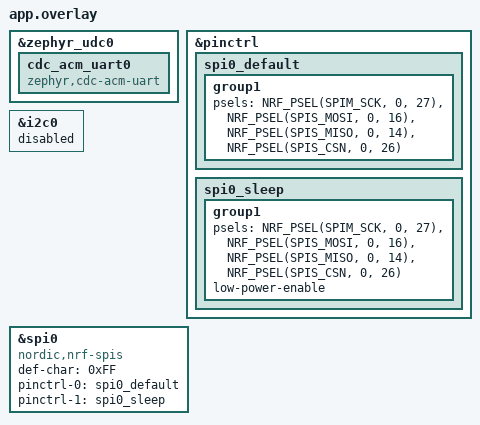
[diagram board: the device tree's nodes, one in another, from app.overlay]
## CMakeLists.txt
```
# SPDX-License-Identifier: Apache-2.0

cmake_minimum_required(VERSION 3.20.0)

find_package(Zephyr REQUIRED HINTS $ENV{ZEPHYR_BASE})
project(ioxp_emu)

target_sources(app PRIVATE
    ${PROJECT_SOURCE_DIR}/src/ipi.c
    ${PROJECT_SOURCE_DIR}/src/main.cpp
    ${PROJECT_SOURCE_DIR}/src/erpc/port/erpc_port_zephyr.cpp
    ${PROJECT_SOURCE_DIR}/src/erpc/port/erpc_threading_zephyr.cpp
    ${PROJECT_SOURCE_DIR}/src/erpc/transport/erpc_zephyr_usb_cdc_transport.cpp
    ${CMAKE_CURRENT_BINARY_DIR}/erpcgen/ioxp_pc2emu_server.cpp
    ${CMAKE_CURRENT_BINARY_DIR}/erpcgen/ioxp_emu2pc_client.cpp
    ${PROJECT_SOURCE_DIR}/../erpc/erpc_c/infra/erpc_server.cpp
    ${PROJECT_SOURCE_DIR}/../erpc/erpc_c/infra/erpc_framed_transport.cpp
    ${PROJECT_SOURCE_DIR}/../erpc/erpc_c/infra/erpc_crc16.cpp
    ${PROJECT_SOURCE_DIR}/../erpc/erpc_c/infra/erpc_message_buffer.cpp
    ${PROJECT_SOURCE_DIR}/../erpc/erpc_c/infra/erpc_simple_server.cpp
    ${PROJECT_SOURCE_DIR}/../erpc/erpc_c/infra/erpc_basic_codec.cpp
    ${PROJECT_SOURCE_DIR}/../erpc/erpc_c/infra/erpc_arbitrated_client_manager.cpp
    ${PROJECT_SOURCE_DIR}/../erpc/erpc_c/infra/erpc_transport_arbitrator.cpp
    ${PROJECT_SOURCE_DIR}/../erpc/erpc_c/infra/erpc_client_manager.cpp
    ${PROJECT_SOURCE_DIR}/../erpc/erpc_c/setup/erpc_setup_mbf_dynamic.cpp
    ${PROJECT_SOURCE_DIR}/../erpc/erpc_c/setup/erpc_arbitrated_client_setup.cpp
    ${PROJECT_SOURCE_DIR}/../erpc/erpc_c/setup/erpc_server_setup.cpp
)

target_include_directories(app PRIVATE
    ${PROJECT_SOURCE_DIR}/src/config
    ${PROJECT_SOURCE_DIR}/src/erpc/transport
    ${PROJECT_SOURCE_DIR}/src/erpc/port
    ${CMAKE_CURRENT_BINARY_DIR}/erpcgen
    ${PROJECT_SOURCE_DIR}/../erpc/erpc_c/infra
    ${PROJECT_SOURCE_DIR}/../erpc/erpc_c/transports
    ${PROJECT_SOURCE_DIR}/../erpc/erpc_c/setup

)

add_custom_command(
    OUTPUT ${CMAKE_CURRENT_BINARY_DIR}/erpcgen/ioxp_pc2emu_server.cpp
           ${CMAKE_CURRENT_BINARY_DIR}/erpcgen/ioxp_emu2pc_client.cpp
    COMMAND erpcgen -o ${CMAKE_CURRENT_BINARY_DIR}/erpcgen ${PROJECT_SOURCE_DIR}/../../shared/interface.erpc
)
```

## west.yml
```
manifest:
  remotes:
    - name: zephyrproject-rtos
      url-base: https://github.com/zephyrproject-rtos
    - name: EmbeddedRPC
      url-base: https://github.com/EmbeddedRPC
  projects:
    - name: zephyr
      remote: zephyrproject-rtos
      revision: zephyr-v3.4.0
      import:
        name-allowlist:
          - cmsis
          - hal_nordic
          - mbedtls
          - mcuboot
          - mcumgr
          - nrf_hw_models
          - segger
          - tinycbor
          - tinycrypt
          - zcbor

    - name: erpc
      remote: EmbeddedRPC
      revision: 1.10.0

  self:
    path: app
```

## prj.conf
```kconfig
CONFIG_USB_COMPOSITE_DEVICE=y
CONFIG_USB_DEVICE_STACK=y
CONFIG_USB_DEVICE_PRODUCT="IOExp"
CONFIG_USB_DEVICE_PID=0x0003
CONFIG_USB_DEVICE_INITIALIZE_AT_BOOT=n
CONFIG_ENTROPY_GENERATOR=y
CONFIG_ENTROPY_DEVICE_RANDOM_GENERATOR=y

CONFIG_LOG=y
CONFIG_USB_DRIVER_LOG_LEVEL_INF=y
CONFIG_USB_DEVICE_LOG_LEVEL_INF=y

CONFIG_SERIAL=y
CONFIG_UART_LINE_CTRL=y

CONFIG_GPIO=y

CONFIG_CPP=y
CONFIG_NEWLIB_LIBC=y
CONFIG_REQUIRES_FULL_LIBCPP=y

CONFIG_HEAP_MEM_POOL_SIZE=8192

CONFIG_SHELL=y
CONFIG_THREAD_RUNTIME_STATS=y
CONFIG_STATS=y
CONFIG_STATS_SHELL=y

CONFIG_PIPES=y

CONFIG_DEBUG_OPTIMIZATIONS=y

CONFIG_MAIN_STACK_SIZE=8192

CONFIG_DEBUG=y

CONFIG_SPI=y
CONFIG_SPI_SLAVE=y
CONFIG_SPI_ASYNC=y
```

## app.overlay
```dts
/*
 * Copyright (c) 2021 Nordic Semiconductor ASA
 *
 * SPDX-License-Identifier: Apache-2.0
 */

&zephyr_udc0 {
	cdc_acm_uart0 {
		compatible = "zephyr,cdc-acm-uart";
	};

};

&pinctrl {

	spi0_default: spi0_default {
		group1 {
			psels = <NRF_PSEL(SPIM_SCK, 0, 27)>, 
			<NRF_PSEL(SPIS_MOSI, 0, 16)>,
			<NRF_PSEL(SPIS_MISO, 0, 14)>,
			<NRF_PSEL(SPIS_CSN, 0, 26)>;

		};
	};

	spi0_sleep: spi0_sleep {
		group1 {
			psels = <NRF_PSEL(SPIM_SCK, 0, 27)>, 
			<NRF_PSEL(SPIS_MOSI, 0, 16)>,
			<NRF_PSEL(SPIS_MISO, 0, 14)>,
			<NRF_PSEL(SPIS_CSN, 0, 26)>;
			low-power-enable;
		};
	};
};

// I2C0 is enabled in the board DTS, but SPI0 cannot be used
// at the same time. Thus we override the status to 'disabled' here
&i2c0 {
	status = "disabled";
};

&spi0 {
	compatible = "nordic,nrf-spis";
	status = "okay";

	def-char = <0xFF>;

	pinctrl-0 = <&spi0_default>;
	pinctrl-1 = <&spi0_sleep>;
	pinctrl-names = "default", "sleep";	
};
```

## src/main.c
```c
/*
 * Copyright (c) 2019 Nordic Semiconductor ASA
 *
 * SPDX-License-Identifier: Apache-2.0
 */
#include <zephyr/kernel.h>
#include <zephyr/device.h>
#include <zephyr/drivers/gpio.h>
#include <zephyr/drivers/uart.h>
#include <string.h>
#include <zephyr/random/rand32.h>

#include <zephyr/usb/usb_device.h>
#include <zephyr/usb/class/usb_hid.h>
#include <zephyr/usb/class/usb_cdc.h>

#define LOG_LEVEL LOG_LEVEL_DBG
LOG_MODULE_REGISTER(main);


#define MOUSE_BTN_REPORT_POS	0
#define MOUSE_X_REPORT_POS	1
#define MOUSE_Y_REPORT_POS	2

#define MOUSE_BTN_LEFT		BIT(0)
#define MOUSE_BTN_RIGHT		BIT(1)
#define MOUSE_BTN_MIDDLE	BIT(2)


#define WELCOME_MSG "Welcome ..."

/* CDC ACM */

static volatile bool data_transmitted;
static volatile bool data_arrived;

static void write_data(const struct device *dev, const char *buf, int len)
{
	uart_irq_tx_enable(dev);

	while (len) {
		int written;

		data_transmitted = false;
		written = uart_fifo_fill(dev, (const uint8_t *)buf, len);
		while (data_transmitted == false) {
			k_yield();
		}

		len -= written;
		buf += written;
	}

	uart_irq_tx_disable(dev);
}

static void cdc_0_int_handler(const struct device *dev, void *user_data)
{
	ARG_UNUSED(user_data);

	uart_irq_update(dev);

	if (uart_irq_tx_ready(dev)) {
		data_transmitted = true;
	}

	if (!uart_irq_rx_ready(dev)) {
		return;
	}
	uint32_t bytes_read;
	uint8_t rx_buffer;

	while ((bytes_read = uart_fifo_read(dev, &rx_buffer, 1))) {
		LOG_INF("char received on CDC0: 0x%02x (%c)", rx_buffer, (char) rx_buffer);
	}

}

static void cdc_1_int_handler(const struct device *dev, void *user_data)
{
	ARG_UNUSED(user_data);

	uart_irq_update(dev);

	if (uart_irq_tx_ready(dev)) {
		data_transmitted = true;
	}

	if (!uart_irq_rx_ready(dev)) {
		return;
	}
	uint32_t bytes_read;
	uint8_t rx_buffer;

	while ((bytes_read = uart_fifo_read(dev, &rx_buffer,1))) {
		LOG_INF("char received on CDC1: 0x%02x (%c)", rx_buffer, (char) rx_buffer);
	}
}

/* Devices */

static void status_cb(enum usb_dc_status_code status, const uint8_t *param)
{
	LOG_INF("Status %d", status);
}

#define DEVICE_AND_COMMA(node_id) DEVICE_DT_GET(node_id),

int main(void)
{
	const struct device *cdc_dev[] = {
		DT_FOREACH_STATUS_OKAY(zephyr_cdc_acm_uart, DEVICE_AND_COMMA)
	};
	BUILD_ASSERT(ARRAY_SIZE(cdc_dev) >= 2, "Not enough CDC ACM instances");
	uint32_t dtr = 0U;
	int ret;

	for (int idx = 0; idx < ARRAY_SIZE(cdc_dev); idx++) {
		if (!device_is_ready(cdc_dev[idx])) {
			LOG_ERR("CDC ACM device %s is not ready",
				cdc_dev[idx]->name);
			return 0;
		}
	}

	ret = usb_enable(status_cb);
	if (ret != 0) {
		LOG_ERR("Failed to enable USB");
		return 0;
	}

	/* Initialize CDC ACM */
	for (int idx = 0; idx < ARRAY_SIZE(cdc_dev); idx++) {
		LOG_INF("Wait for DTR on %s", cdc_dev[idx]->name);
		while (1) {
			uart_line_ctrl_get(cdc_dev[idx],
					   UART_LINE_CTRL_DTR,
					   &dtr);
			if (dtr) {
				break;
			} else {
				/* Give CPU resources to low priority threads. */
				k_sleep(K_MSEC(100));
			}
		}

		LOG_INF("DTR on device %s", cdc_dev[idx]->name);
	}


	LOG_INF("Waiting for 1s");
	/* Wait 1 sec for the host to do all settings */
	k_busy_wait(USEC_PER_SEC);

	uart_irq_callback_set(cdc_dev[0], cdc_0_int_handler);
	uart_irq_callback_set(cdc_dev[1], cdc_1_int_handler);

	write_data(cdc_dev[0], WELCOME_MSG, strlen(WELCOME_MSG));
	write_data(cdc_dev[0], cdc_dev[0]->name, strlen(cdc_dev[0]->name));
	write_data(cdc_dev[1], WELCOME_MSG, strlen(WELCOME_MSG));
	write_data(cdc_dev[1], cdc_dev[1]->name, strlen(cdc_dev[1]->name));

	uart_irq_rx_enable(cdc_dev[0]);
	uart_irq_rx_enable(cdc_dev[1]);

	while (true) {
		k_sleep(K_MSEC(100));
	}

}
```

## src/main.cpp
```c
/*
 * Copyright (c) 2019 Nordic Semiconductor ASA
 *
 * SPDX-License-Identifier: Apache-2.0
 */
#include <zephyr/kernel.h>
#include <zephyr/device.h>
#include <zephyr/drivers/gpio.h>
#include <zephyr/drivers/uart.h>
#include <string.h>
#include <zephyr/random/rand32.h>

#include <zephyr/usb/usb_device.h>
#include <zephyr/usb/class/usb_hid.h>
#include <zephyr/usb/class/usb_cdc.h>

#include <string>
#include "ioxp_pc2emu_server.h"

#include <erpc_server_setup.h>
#include <erpc_arbitrated_client_setup.h>
#include "erpc_zephyr_usb_cdc_transport.hpp"

#include "ipi.h"

using namespace std;

#define LOG_LEVEL LOG_LEVEL_DBG
LOG_MODULE_REGISTER(main);

static void status_cb(enum usb_dc_status_code status, const uint8_t *param)
{
	LOG_INF("Status %d", status);
}


/************************************************************************************************
 * Server Methods ...
 ***********************************************************************************************/

status_t sendCanMsg(const rvc_msg_t * txInput){

	int rc;
	status_t status = ERROR;

	char temp_buff[256];
	char* wp = temp_buff;
	char* ep = wp + sizeof(temp_buff);
	wp = wp + snprintf(wp, ep - wp,"CAN ID: 0x%08x - Data:", txInput->id);
	for(uint8_t i=0; i < 8; i++){
	 	wp = wp + snprintf(wp, ep - wp,"0x%02x ", txInput->data[i]);
	}
	*wp = '\0';

	LOG_DBG("Sending: %s", temp_buff);

	rc = ipi_send_can_msg(txInput);
	if (rc == 0) {
		status = SUCCESS;
	}
	return status;
}

int main(void)
{
	uint32_t dtr = 0U;
	int ret;

	const struct device *cdc_dev;
	cdc_dev = DEVICE_DT_GET_ONE(zephyr_cdc_acm_uart);

	if (!device_is_ready(cdc_dev)) {
		LOG_ERR("CDC ACM device not ready");
		return 0;
	}

	ret = usb_enable(status_cb);
	if (ret != 0) {
		LOG_ERR("Failed to enable USB");
		return 0;
	}

	/* Initialize CDC ACM */
	while (true) {
		uart_line_ctrl_get(cdc_dev, UART_LINE_CTRL_DTR, &dtr);
		if (dtr) {
			break;
		} else {
			/* Give CPU resources to low priority threads. */
			k_sleep(K_MSEC(100));
		}
	}

	LOG_INF("Waiting for 1s");
	/* Wait 1 sec for the host to do all settings */
	k_busy_wait(USEC_PER_SEC);


	erpc_transport_t arbitrated_transport;
	erpc_transport_t transport = reinterpret_cast<erpc_transport_t>(
		new erpc::ZephyrUsbCdcTransport(cdc_dev)
	);
	erpc_mbf_t message_buffer_factory = erpc_mbf_dynamic_init();

	erpc_client_t client = erpc_arbitrated_client_init(transport, message_buffer_factory, &arbitrated_transport);
	if (client == NULL) {
		LOG_ERR("Failed to initialize eRPC arbitrated client");
	}

	LOG_INF("Setting up server ...");
	auto server = erpc_server_init(arbitrated_transport, message_buffer_factory);

	LOG_INF("Adding service to server ... ");
	erpc_add_service_to_server(server, create_IoExpanderEmulator_service());

	LOG_INF("Starting IPI");
	ipi_init();

	LOG_INF("Starting server ...");
	erpc_server_run(server);

	// shouuld never get here ....

	while (true) {
		k_sleep(K_MSEC(100));
	}

}
```

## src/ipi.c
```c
#include "ipi.h"
#include <zephyr/kernel.h>
#include <zephyr/logging/log.h>
#include <zephyr/drivers/gpio.h>
#include <zephyr/drivers/spi.h>
#include <string.h>
#include <stdio.h>
#include "ioxp_emu2pc.h"

#include "rvmn_spi.h"

#define IPI_VERSION(major, minor, patch) ((0x0FU & major) << 12 | (0x0FU & minor) << 8 | (0xFFU & patch))

#define GPIO_NAME "GPIO_0"
#define SPI_RDY_PIN 11

#define MY_GPIO DT_NODELABEL(gpio0)

#define SPI_DMA_OP_CNT 1U

#define LOG_LEVEL LOG_LEVEL_DBG
LOG_MODULE_REGISTER(ipi);

const struct device *ipi_spi_dev = DEVICE_DT_GET(DT_NODELABEL(spi0));
const struct device *gpio_dev = DEVICE_DT_GET(DT_NODELABEL(gpio0));

struct k_thread ipi_transceive_thread_data;
K_THREAD_STACK_DEFINE(ipi_transceive_thread_stack, 2048);

struct k_thread ipi_rxproc_thread_data;
K_THREAD_STACK_DEFINE(ipi_rxproc_thread_stack, 2048);

static void ipi_timer_func(struct k_timer *timer_id){
	gpio_pin_toggle(gpio_dev, SPI_RDY_PIN);
}

K_TIMER_DEFINE(ipi_timer, ipi_timer_func, NULL);
K_MUTEX_DEFINE(ipi_mutex);
K_SEM_DEFINE(ipi_sem, 0, 1);


static struct spi_config ipi_spi_config;
struct SPIS_tuMOSI spi_rx_buf[2];
struct SPIS_tuMISO spi_tx_buf[2];
static struct spi_buf spi_tx_buf_pack[SPI_DMA_OP_CNT] = {
        {.buf = spi_tx_buf[0].spi_dma_block, .len = SPI_TRANSFER_SIZE},
};
static struct spi_buf spi_rx_buf_pack[SPI_DMA_OP_CNT] = {
        {.buf = spi_rx_buf[0].spi_dma_block, .len = SPI_TRANSFER_SIZE},
};

static const struct spi_buf_set spi_tx_buf_set_pack = {
        .buffers = spi_tx_buf_pack,
        .count = SPI_DMA_OP_CNT,  /* must be set to 1 otherwise the Nordic SPI driver will reject it  */
};
static const struct spi_buf_set spi_rx_buf_set_pack = {
        .buffers = spi_rx_buf_pack,
        .count = SPI_DMA_OP_CNT,  /* must be set to 1 otherwise the Nordic SPI driver will reject it  */
};

// 'active' buffers are those allocated for SPI transceive, the
// 'inactive' those that can be written to from host/data is processed from for
// upload to host
static struct SPIS_tuMOSI* active_rx_buffer = &spi_rx_buf[0];
static struct SPIS_tuMOSI* inactive_rx_buffer = &spi_rx_buf[1];
static struct SPIS_tuMISO* active_tx_buffer = &spi_tx_buf[0];
static struct SPIS_tuMISO* inactive_tx_buffer = &spi_tx_buf[1];

/**
 * @brief Calculates 32-bit checksum
 *
 * @param data pointer to data block checksum shall be calculated over
 * @param len  number of 32bit words checksum shall be calculated over
 * @return uint32_t the calculated checksum
 */
static uint32_t u32CalculateCS(const uint32_t *data, uint16_t len) {

	uint32_t checksum = 0x00000000;

    for (uint16_t i = 0; i < len; i++) {
        checksum += *data;
        data++;
    }

    return checksum;
}

/**
 * @brief Calculate 8-bit checksum
 *
 * @param data pointer to data block checksum is to be calculated over
 * @param len number of 8bit words checksum will be calculated over
 * @return uint8_t the calculated checksum
 */
static uint8_t u8CalculateCS(const uint8_t* data, uint16_t len) {

	uint8_t checksum = 0x00;
	for (uint16_t i = 0; i < len; i++) {
		checksum += *data;
		data++;
	}

	return checksum;
}

static void ipi_transceive_thread_func(void*, void*, void*) {

	int rc;
	struct SPIS_tuMOSI* tmp_rx_buffer; // this one is for when swapping active/passive
	struct SPIS_tuMISO* tmp_tx_buffer; // this one is for when swapping active/passive


	if (!device_is_ready(gpio_dev)) {
        /* Not ready, do not use */
		LOG_ERR("GPIO Port is not ready ...");
        return;
	}
	rc = gpio_pin_configure(gpio_dev, SPI_RDY_PIN, GPIO_OUTPUT_ACTIVE);
	if (rc != 0){
		LOG_ERR("Configuring SPI Ready pin failed");
		return;
	}

	if (!device_is_ready(ipi_spi_dev)) {
		LOG_ERR("SPI device is not ready ...");
		return;
	}

	ipi_spi_config.frequency = SPI_FREQUENCY;
    ipi_spi_config.operation = (SPI_OP_MODE_SLAVE | SPI_WORD_SET(8));
    ipi_spi_config.slave = 1U;

	memset(active_tx_buffer->spi_dma_block, 0x00, sizeof(active_tx_buffer->spi_dma_block));

	// Initilaize the TX IPI structure currently active with sensible defaults ...
	active_tx_buffer->u16PSinfo          = IPI_VERSION(1, 0, 0); 	// IPI version
    active_tx_buffer->u16SwVer           = IPI_VERSION(0, 3, 0);    // Simulate NXP software version
    active_tx_buffer->u16VBATT_MON       = 0x848;
    active_tx_buffer->u16VCC_Switched    = 0x91c;
    active_tx_buffer->u16DETECT_VHBRIDGE = 0;
	active_tx_buffer->u16SysInfoReserved = 0;
    active_tx_buffer->ign_mon_adc        = 0;

	active_tx_buffer->IO.u16Inp_1[ 0] = 0x803e;
    active_tx_buffer->IO.u16Inp_1[ 1] = 0x8068;
    active_tx_buffer->IO.u16Inp_1[ 2] = 0x8068;
    active_tx_buffer->IO.u16Inp_1[ 3] = 0x8110;
    active_tx_buffer->IO.u16Inp_1[ 4] = 0x80bc;
    active_tx_buffer->IO.u16Inp_1[ 5] = 0x80e6;
    active_tx_buffer->IO.u16Inp_1[ 6] = 0x0;
    active_tx_buffer->IO.u16Inp_1[ 7] = 0x00;
    active_tx_buffer->IO.u16Inp_1[ 8] = 0x99c2;
    active_tx_buffer->IO.u16Inp_1[ 9] = 0x99b4;
    active_tx_buffer->IO.u16Inp_1[10] = 0x99c8;
    active_tx_buffer->IO.u16Inp_1[11] = 0x9a0b;
    active_tx_buffer->IO.u16Inp_1[12] = 0x862c;
    active_tx_buffer->IO.u16Inp_1[13] = 0x85ac;

	memcpy(
		&inactive_tx_buffer->spi_dma_block,
		&active_tx_buffer->spi_dma_block,
		sizeof(inactive_tx_buffer->spi_dma_block)
	);

	inactive_tx_buffer->u32RollCnt++;

	// Start timer - this will start toggling the SPI Ready signal
	k_timer_start(&ipi_timer, K_MSEC(10), K_MSEC(10));

	while (true) {

		// Update checksums on the buffer about to be transmitted
		#pragma GCC diagnostic push
		#pragma GCC diagnostic ignored "-Waddress-of-packed-member"
		active_tx_buffer->u32CSinfo = u32CalculateCS((uint32_t*)&active_tx_buffer->u16PSinfo, 2);
		active_tx_buffer->IO.u32CS = u32CalculateCS(
			(uint32_t*)&active_tx_buffer->IO,
			sizeof(active_tx_buffer->IO)/sizeof(uint32_t) - 1
		);
		#pragma GCC diagnostic pop
		active_tx_buffer->u32CS = u32CalculateCS(
			(uint32_t*)active_tx_buffer,
			sizeof(*active_tx_buffer)/sizeof(uint32_t) - 1
		);

		// run SPI transaction
		// We are SPI Slave, the SPI ready signal (a GPIO) is used to signal to the
		// master that we are ready to receive (The master MCU is looking for a falling edge).
		// we should be ok setting the RDY pin before calling spi_transceive(), otherwise we
		// might have to do this in a support thread...

		spi_transceive(
			ipi_spi_dev,
			&ipi_spi_config,       // const struct spi_config *config,
			&spi_tx_buf_set_pack,  // const struct spi_buf_set *tx_bufs,
			&spi_rx_buf_set_pack   // const struct spi_buf_set *rx_bufs,
		);


		// lock mutex to protect IPI buffers
		k_mutex_lock(&ipi_mutex, K_FOREVER);

		// Switch IPI buffers
		tmp_rx_buffer = active_rx_buffer;
		active_rx_buffer = inactive_rx_buffer;
		inactive_rx_buffer = tmp_rx_buffer;

		tmp_tx_buffer = active_tx_buffer;
		active_tx_buffer = inactive_tx_buffer;
		inactive_tx_buffer = tmp_tx_buffer;

		spi_tx_buf_pack[0].buf = active_tx_buffer->spi_dma_block;
		spi_rx_buf_pack[0].buf = active_rx_buffer->spi_dma_block;

		// copy TX data buffer
		// we want to start the 'fresh' buffer with the same state as the one about to be
		// transmitted. At least for all the digital or analog input this is ... CAN messages
		// should be cleared out.
		memcpy(
			&inactive_tx_buffer->spi_dma_block,
			&active_tx_buffer->spi_dma_block,
			sizeof(inactive_tx_buffer->spi_dma_block)
		);
		memset(&inactive_tx_buffer->aCANMsg, 0x0, sizeof(inactive_tx_buffer->aCANMsg));

		// increment the rolling counter
		inactive_tx_buffer->u32RollCnt++;

		// unlock mutex - free to write to the 'fresh' buffer while the other one is being
		// transmitted
		k_mutex_unlock(&ipi_mutex);

		// signal the rx processing task that new data is available for processing
		k_sem_give(&ipi_sem);

		// check the interval between this and previous transceive.
		// Issue a warning if interval too large
		// TODO:
	}
}

static void ipi_rxproc_thread_func(void*, void*, void*) {


	while(true){
		k_sem_take(&ipi_sem, K_FOREVER);

		// TODO: validate IPI frame checksum
		LOG_DBG("starting rx proc");

		// Extract CAN Messages ...
		for (int i=0; i<SPIS_nCANMsgTX; i++){
			if (inactive_rx_buffer->aCANMsg[i].u16ID28_16 & 0x8000) {

				LOG_DBG(
					"spi-pos: %d, SA: 0x%02x, DGN: 0x%03x, PRI: 0x%x",
					i,
					inactive_rx_buffer->aCANMsg[i].id.sa,
					inactive_rx_buffer->aCANMsg[i].id.dgn,
					inactive_rx_buffer->aCANMsg[i].id.pri
				);

				// TODO: validate checksum

				rvc_msg_t m;
				memcpy(&m.id, inactive_rx_buffer->aCANMsg[i].id.canid, sizeof(m.id));
				// bits 15:13 are control bits for the IPI trasnmission, don't belong
				// to RV-C.
				// [15] = Message valid bit, set to 1.
                // [14] = Extended ID bit, set to 1
                // [13] = 1 for TX (0 for RX)
				// mask those out ....
				m.id &= 0x1fffffff;
				memcpy(m.data, inactive_rx_buffer->aCANMsg[i].u8Data, sizeof(m.data));
				canMsgRcvd(&m);
			}
		}
	}
}

int ipi_init(void){

	k_thread_create(
		&ipi_transceive_thread_data,
		ipi_transceive_thread_stack,
		K_THREAD_STACK_SIZEOF(ipi_transceive_thread_stack),
		ipi_transceive_thread_func, NULL, NULL, NULL,
		2, 0, K_NO_WAIT
	);

	k_thread_create(
		&ipi_rxproc_thread_data,
		ipi_rxproc_thread_stack,
		K_THREAD_STACK_SIZEOF(ipi_rxproc_thread_stack),
		ipi_rxproc_thread_func, NULL, NULL, NULL,
		2, 0, K_NO_WAIT
	);

    return 0;
}


int ipi_send_can_msg(const rvc_msg_t *msg){

	int status = -EBUSY;

	k_mutex_lock(&ipi_mutex, K_FOREVER);

	// Interate  over the CAN message slots in the IPI data structure of the currently
	// writable buffer and see whether there's a free slot available.
	// If so load message data into this slot. If not we'll return -EBUSY
	for (int i = 0; i < SPIS_nCANMsgRX; i++){
		if (inactive_tx_buffer->aCANMsg[i].u16ID28_16 == 0x0) {

			memcpy(
				&inactive_tx_buffer->aCANMsg[i].id.canid, &msg->id,
				sizeof(inactive_tx_buffer->aCANMsg[i].id.canid)
			);

			inactive_tx_buffer->aCANMsg[i].u16ID28_16 |= 0x8000;

			memcpy(
				&inactive_tx_buffer->aCANMsg[i].u8Data, &msg->data,
				sizeof(inactive_tx_buffer->aCANMsg[i].u8Data)
			);

			inactive_tx_buffer->aCANMsg[i].u8DLC = 8; // DLC is always 8 for RV-C

			inactive_tx_buffer->aCANMsg[i].u8CS = u8CalculateCS(
				(uint8_t*) &inactive_tx_buffer->aCANMsg[i],
				sizeof(inactive_tx_buffer->aCANMsg[i]) - 1
			);

			status = 0;

			break;
		}
	}

	k_mutex_unlock(&ipi_mutex);

    return status;
}
```

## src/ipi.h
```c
#ifndef __IPI_H__
#define __IPI_H__

#include "ioxp_emu2pc.h"

#ifdef __cplusplus
extern "C" {
#endif

/**
 * @brief Initialize and start IPI service
 *
 * @return int
 */
int ipi_init(void);

/**
 * @brief enqueue a CAM Message for transmission
 *
 * @param msg CAN Message to be transmitted
 * @return int
 */
int ipi_send_can_msg(const rvc_msg_t* msg);

#ifdef __cplusplus
}
#endif

#endif
```

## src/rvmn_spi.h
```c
#ifndef RVMN_SPI_H
#define RVMN_SPI_H

#include <stdbool.h>
#include <string.h>
#include <stdio.h>

#include <stdint.h>
#include <errno.h>
//#include <misc/printk.h>
#include <zephyr/device.h>
//#include <gpio.h>
#include <errno.h>
#include <zephyr/kernel.h>
//#include <init.h>
//#include <soc.h>
//#include <sys_io.h>
//#include <misc/util.h>
//#include <spi.h>

#define BUFF_LENGTH 			600        	/**< Transfer length. */
#define NUMBER_OF_XFERS 		3
#define BYTES_PR_XFER   		600/*200*/ 		/* Number of bytes per transfer */
#define SPI_TRANSFER_SIZE 600

#define SPIM_DRV_NAME 			"SPI_0"
#define SPI_CS_PIN      		31
#define SPI_READY_PIN_IN        19
#define SPI_FREQUENCY 			/*8000000U*/1000000

/* Inter-Processor Interface Packet Structure Info */
#define IPI_PSINFO(MAJOR, MINOR) 	((MAJOR << 8) | (MINOR))

/* Invalid entry used at 1st SPI transfer */
#define IPI_PSINFO_V0_0			IPI_PSINFO(0, 0)

#define IPI_PSINFO_V1_4			IPI_PSINFO(1, 4)
#define IPI_PSINFO_V3_0			IPI_PSINFO(3, 0)
#define IPI_PSINFO_V4_0			IPI_PSINFO(4, 0)

/* TMC CR0003 - IGN_MON + parking brake */
#define IPI_PSINFO_V5_0			IPI_PSINFO(5, 0)

/* NXP v1.9 reports this packet structure */
#define IPI_PSINFO_V1_2			IPI_PSINFO(1, 2)

/* The following settings are specific to BMPRO Connect*/
#define INPUT_CNT 8
#define IPI_PS_V1_2_SUPPORTED true
#define IPI_PS_V1_4_SUPPORTED true
#define IPI_PS_V3_0_SUPPORTED false
#define IPI_PS_V4_0_SUPPORTED true
#define IPI_PS_V5_0_SUPPORTED false

typedef union {
    struct {
        uint32_t    sa             :  8;
        uint32_t    dgn            : 18;
        uint32_t    pri            :  3;
        uint32_t    validity       :  3;       /* this is not a part of the RV-C standard but that of Setec CAN-SPI protocol */
    } __attribute__ ((packed));             /* RV-C id as per J1939 + 3 validity bits at bit 29-31   */
    uint16_t    canid[2];                      /* standard 29-bit CAN id + 3 validity bits at bit 29-31 */
} RVC_tunId;

// CAN Message Structure
typedef struct CAN_stMsg
{
    union {
        struct {
            uint16_t u16ID15_0;  // ID bits 0 to 15
            uint16_t u16ID28_16; // Message valid bit, Extend identifier and direction bits, ID bits 16 to 28
        };
        RVC_tunId id;
    };

    union {
        uint16_t u16Data[4];     // Data (two bytes as in the CAN message interface data registers)
        uint8_t u8Data[8];       // Data (single bytes as shown in the RVMCwithLEDDsiplay_V1_1.docx document)
    };
    uint8_t  u8DLC;      // DLC (bit0 to 3 only)
    uint8_t  u8CS;       // Message Checksum
} __attribute__ ((packed)) CAN_tstMsg;

#define SPIS_nMDatasize 600             // Master Data size in bytes
#define SPIS_nSDatasize SPIS_nMDatasize // Slave  Data size in bytes must be same as Master

#define SPIS_nOutp_0 	8	// Number of Outputs Full Bridge
#define SPIS_nOutp_1 	4	// Number of Outputs HSD 10A
#define SPIS_nOutp_2 	8	// Number of Outputs HSD Dimmable 5A
#define SPIS_nOutp_3 	18	// Number of Outputs HSD 500mA
#define SPIS_nOutp_4 	4	// Number of Outputs LSD 500mA
#define SPIS_nOutp_5 	6	// Number of Outputs HSD 5A (not dimmable)

#define SPIS_nInp_0	8	// Byte count only, digital input packing depends on IPI PS structure version

#define SPIS_nInp_1     14  // Number of Inputs A2D

#define SPIS_nCANMsgRX  32  // Number of CAN Messages received
#define SPIS_niCANMsgSWITCHSTATUS 0 // The SWITCH_STATUS message from RVMC is the first message in the array/

struct output_monitor {
	uint32_t state : 2;
	uint32_t err_type : 2;
	uint32_t current_ma : 28; /* mA */
};

int RVM_spi_get_pwm_info(uint8_t on_off_i, struct output_monitor *om);

//
// Type Definition of Data from Slave
//
typedef struct SPIS_tuMISO { // Slave Data Structure as defined in RVMN_InterProcessorInterface_v1.5.xlsx
	union {
		struct {
			// Info
			uint16_t u16PSinfo; // Packet Structure Info (Hbyte = Major, LByte = Minor Version)
			uint16_t u16SwVer; // Software Version
			uint32_t u32RollCnt; // Rolling Counter, roll over after reaching max value.
			uint32_t u32CSinfo; // Block Checksum (Info)
			struct { // I/O Sub-Structure
				uint16_t u16Outp_0[SPIS_nOutp_0]; // Outputs Full Bridge
				uint16_t u16Outp_1[SPIS_nOutp_1]; // Outputs HSD 10A
				union {
					uint32_t u32Outp_2[SPIS_nOutp_2]; // Outputs HSD Dimmable 5A
					uint16_t u16Outp_2[SPIS_nOutp_2 * 2]; // Outputs HSD Dimmable 5A
				};
				uint8_t u8Outp_3[SPIS_nOutp_3]; // Outputs HSD 500mA
				uint8_t u8Outp_4[SPIS_nOutp_4]; // Outputs LSD 500mA
				uint8_t u8Outp_5[SPIS_nOutp_5]; // Outputs HSD 5A (not dimmable)

				uint8_t u8Inp_0[SPIS_nInp_0]; // Inputs Digital
				uint16_t u16Inp_1[SPIS_nInp_1] __attribute__((packed)); // Inputs A2D
				uint32_t u32CS __attribute__((packed)); // Block Checksum (I/O Sub-Structure)
			} __attribute__((packed)) IO; // IO Status

			CAN_tstMsg aCANMsg[SPIS_nCANMsgRX]; // CAN Messages received, SWITCH_STATUS from RVMC is first element.
			// System Info
			// Median (5) filtered A2D value, A2D-Value: bit[0..11] Reserved: bit[12..15] (set to 0)
			uint16_t u16VBATT_MON; // Battery Voltage
			uint16_t u16VCC_Switched; // Sensor Supply Voltage
			uint16_t u16DETECT_VHBRIDGE; // H-Brideg Supply Voltage
			uint16_t u16SysInfoReserved; // Reserved (set to 0)
			uint16_t ign_mon_adc; // Ignition Monitor (analogue) currently only supported by PS v5.0

			uint8_t u8Reserve[2]; // Reserved, set to 0.

			uint32_t u32CS __attribute__((packed)); // Block Checksum (Overall)
		};
		struct {
			uint8_t spi_dma_block[SPI_TRANSFER_SIZE];
			/*
			uint8_t spi_dma_block0[BYTES_PR_XFER];
			uint8_t spi_dma_block1[BYTES_PR_XFER];
			uint8_t spi_dma_block2[BYTES_PR_XFER];
			*/

		} __attribute__((packed));
	};
} __attribute__((packed)) SPIS_tuMISO;

#define SPIS_nOCtp_0 	2	// Number of bytes for Output Control Full Bridge
#define SPIS_nOCtp_1 	1	// Number of bytes for Outputs HSD 10A
#define SPIS_nOCtp_2 	16	// Number of bytes for Outputs HSD Dimmable 5A
#define SPIS_nOCtp_3 	3	// Number of bytes for Outputs HSD 500mA
#define SPIS_nOCtp_4 	1	// Number of bytes for Outputs LSD 500mA
#define SPIS_nOCtp_5 	1	// Number of bytes for Outputs HSD 5A (newer hardware is dimmable)

#define SPIS_nOCtp_mask_2 	1	// Number of bytes for Mask Outputs HSD Dimmable 5A
#define SPIS_nOC_reserved 	2	// Number of bytes Reserved

#define SPIS_nCANMsgTX  4       // Number of CAN Messages

//
// Type Definition of Data from Master
//
typedef struct SPIS_tuMOSI { // Master Data Structure as defined in RVMN_InterProcessorInterface_v1.5.xlsx
	union {
		struct {
			// Info
			uint16_t u16PSinfo; // Packet Structure Info
			uint8_t version_minor;
			uint8_t version_major;
			uint32_t u32RollCnt; // Rolling Counter, roll over after reaching max value.
			uint32_t u32CSinfo; // Block Checksum (Info)
			struct { // Output Control Sub-Structure
				uint8_t u8OCtp_0[SPIS_nOCtp_0]; // Output for Full Bridges (2bits/output)
				uint8_t u8OCtp_1[SPIS_nOCtp_1]; // Outputs HSD 10A (1bit/output)
				uint16_t u16OCtp_2[(SPIS_nOCtp_2 / 2)] __attribute__((packed)); // Outputs HSD Dimmable 5A, PWM setting 0 to 65535
				uint8_t u8OCtp_3[SPIS_nOCtp_3]; // Outputs HSD 500mA (1bit/output)
				uint8_t u8OCtp_4[SPIS_nOCtp_4]; // Outputs LSD 500mA (1bit/output)
				uint8_t u8OCtp_5[SPIS_nOCtp_5]; // Outputs HSD 5A (1bit/output)
				uint8_t u8OCtp_mask_0[SPIS_nOCtp_0]; // Mask for Full Bridges (2bits/output)
				uint8_t u8OCtp_mask_1[SPIS_nOCtp_1]; // Mask outputs HSD 10A (1bit/output)
				uint8_t u8OCtp_mask_2[SPIS_nOCtp_mask_2]; // MAsk outputs HSD Dimmable 5A, PWM setting 0 to 65535
				uint8_t u8OCtp_mask_3[SPIS_nOCtp_3]; // MAsk outputs HSD 500mA (1bit/output)
				uint8_t u8OCtp_mask_4[SPIS_nOCtp_4]; // MAsk outputs LSD 500mA (1bit/output)
				uint8_t u8OCtp_mask_5[SPIS_nOCtp_5]; // MAsk outputs HSD 5A (1bit/output)

				uint8_t u8OCHBRlyOffDly; // H-Bridge relay turn-off delay
				uint8_t u8OC_reserved[SPIS_nOC_reserved]; // Reserved for future use

				uint32_t u32CS __attribute__((packed)); // Sub-Structure Checksum
			} __attribute__((packed)) OC; // End of Output Control Sub-Structure

			struct { // Output Configuration Sub-Structure
				// Full Bridges
				uint8_t u8OCfgstalltp_0[SPIS_nOutp_0]; // Stall current threshold, 250mA resolution
				uint8_t u8OCfgstalldlytp_0[SPIS_nOutp_0]; // Stall current switch off delay, 50ms resolution
				// HSD 10A
				uint8_t u8OCfgovertp_1[SPIS_nOutp_1]; // Over current threshold, 250mA resolution
				// HSD Dimmable 5A
				uint8_t u8OCfgovertp_2[SPIS_nOutp_2]; // Over current threshold, 250mA resolution
				// HSD 500mA
				uint8_t u8OCfgovertp_3[SPIS_nOutp_3]; // Over current threshold, 250mA resolution
				// LSD 500mA
				uint8_t u8OCfgovertp_4[SPIS_nOutp_4]; // Over current threshold, 250mA resolution
				// HSD 5A (not dimmable)
				uint8_t u8OCfgovertp_5[SPIS_nOutp_5]; // Over current threshold, 250mA resolution

				uint32_t u32CS __attribute__((packed)); // Sub-Structure Checksum
			} __attribute__((packed)) OCfg; // End of Output Configuration Sub-Structure

			CAN_tstMsg aCANMsg[SPIS_nCANMsgTX]; // CAN Messages to be sent

			// System Info
			uint8_t u8LowPowerModeInfo; // bit0: LPM1 (ECO mode) status - 0b = OFF; 1b = ACTIVE
				// bit1: LPM2 (Storage mode) status - 0b = OFF; 1b = ACTIVE
				// bit[2..7]: Reserved (set to 0)
			uint8_t u8USBPowerCmd;

			struct {
				uint16_t u16OCtp_5_pwm[SPIS_nOutp_5];
				uint32_t u32CS; // Sub-Structure Checksum
			} __attribute__((packed)) pwm1_ctl;
			uint8_t u8Reserve[410]; // Reserved, set to 0.
			uint32_t u32CS __attribute__((packed)); // Block Checksum
		};
		struct {
			/*
			uint8_t spi_dma_block0[BYTES_PR_XFER];
			uint8_t spi_dma_block1[BYTES_PR_XFER];
			uint8_t spi_dma_block2[BYTES_PR_XFER];
			*/
			uint8_t spi_dma_block[SPI_TRANSFER_SIZE];

		} __attribute__((packed));
	};
} __attribute__((packed)) SPIS_tuMOSI;

/* Transmit Buffer */
extern SPIS_tuMOSI SPIS_stuMData; // Data from Master

/* Receive Buffer */
extern SPIS_tuMISO SPIS_stuSData; // Data from Slave


/* Global spi semaphore */
extern struct k_sem g_spi_sem;

#endif // #ifndef RVMN_SPI_H
```
